# YTM32B1ME1 register map
Vendor: YTMicro; File version: 1.0
CPU: CM33 r0p4, little endian, MPU, FPU, 2 interrupt priority bits
Registers are 32-bit, read-write, reset 0x0 unless marked. A register's access mark holds for its fields unless they carry their own. Offsets are from the block's base; [hi:lo] are bit positions; {n}, {i} and the like mark numbered series.

## REGFILE — Register File
Base 0x40184000; register names take the prefix REGFILE_
{0x0+4i} DR{i} (i=0..7)
  [31:0] DATA — The data value stored at register file block. The register is only reseted by POR.

## GPIOA — General Purpose Input/Output
Base 0x40044000; register names take the prefix GPIOA_
0x00 PDOR
  [31:0] PDO — When configured for general-purpose output, it shows the logic level on the corresponding pin.
0x04 PSOR wo
  [31:0] PSO — Writing to this register will update the contents of the corresponding bit in PDOR.
    0=No change; 1=Corresponding bit in PDOR is set to logic 1
0x08 PCOR wo
  [31:0] PCO — Writing to this register will update the contents of the corresponding bit in PDOR.
    0=No change; 1=Corresponding bit in PDOR is set to logic 0
0x0C PTOR wo
  [31:0] PTO — Writing to this register will update the contents of the corresponding bit in PDOR.
    0=No change; 1=Corresponding bit in PDOR is set to the inverse of its existing logic state
0x10 PDIR ro
  [31:0] PDI — When configured for digital function, it shows the logic level on the corresponding pin. ewline When configured for analog function, it always reads 0.
0x14 POER
  [31:0] POE — Configure the corresponding pin for output.
    0=Port output disable; 1=Port output enable
0x18 PIER reset 0xFFFFFFFF
  [31:0] PIE — Configure the corresponding pin for input.
    0=Port input disable; 1=Port input enable
0x1C PIFR
  [31:0] PIF — Indicate the detection for the defined event in PCTRL[IRQC] of the corresponding pin.
    0=No event detected; 1=The event defined in PCTRL[IRQC] is detected
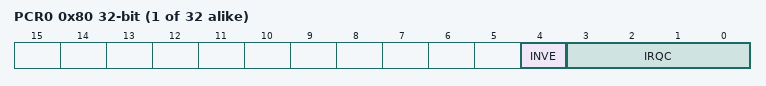
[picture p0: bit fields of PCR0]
{0x80+4i} PCR{i} (i=0..31)
  [4] INVE — Invert the input logic level when configured for digital function.
  [3:0] IRQC
    0=Disabled; 1=DMA request on rising edge; 2=DMA request on falling edge; 3=DMA request on either edge; 8=Interrupt when logic 0; 9=Interrupt on rising-edge; 10=Interrupt on falling-edge; 11=Interrupt on either edge; 12=Interrupt when logic 1

## GPIOB — General Purpose Input/Output
Base 0x40044100; register names take the prefix GPIOB_
Registers as GPIOA.

## GPIOC — General Purpose Input/Output
Base 0x40044200; register names take the prefix GPIOC_
Registers as GPIOA.

## GPIOD — General Purpose Input/Output
Base 0x40044300; register names take the prefix GPIOD_
Registers as GPIOA.

## GPIOE — General Purpose Input/Output
Base 0x40044400; register names take the prefix GPIOE_
Registers as GPIOA.

## PCTRLA — PORT Control
Base 0x40048000; register names take the prefix PCTRLA_
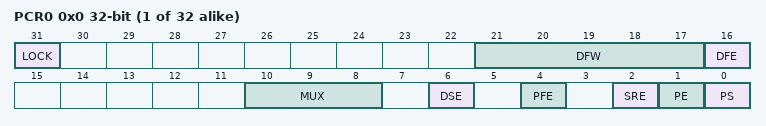
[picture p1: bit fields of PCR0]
{0x0+4i} PCR{i} (i=0..31) — Port control register
  [31] LOCK — Lock Enable configuration for digital pin muxing.
    0=Lock disable; 1=Lock enable, PCR's other bits and related GPIO's output register(PDOR,PSOR,PCOR,PTOR,POER) will be locked until write 0 to this bit
  [21:17] DFW — The digital filter configuration is valid in all digital pin muxing modes. Glitches that are longer than this register setting will pass through the digital filter, and glitches that are equal to or less than this register setting are filtered. Changing the filter length must be done only after all filters are disabled.
  [16] DFE
  [10:8] MUX — Not all pin muxing slots are implemented. Unimplemented pin muxing slots are reserved. Please refer to pinmux table for detailed peripheral functions. The corresponding pin is configured in the following pin muxing slot as follows:
    0=Alternative 0, Analog function, digital function is disabled; 1=Alternative 1, GPIO function; {v}=Alternative {v} (v=2..7)
  [6] DSE — Drive strength configuration for digital pin muxing.
    0=Low drive strength, if the pin is configured as a digital output; 1=High drive strength, if the pin is configured as a digital output
  [4] PFE — Passive filter configuration for digital pin muxing.
    0=Passive input filter is disabled; 1=Passive input filter is enabled, if the pin is configured as a digital input
  [2] SRE — Slew rate configuration for digital pin muxing.
    0=Fast slew rate, if the pin is configured as a digital output; 1=Slow slew rate, if the pin is configured as a digital output
  [1] PE — Pull configuration for digital pin muxing.
    0=Internal pullup or pulldown resistor is not enabled; 1=Internal pullup or pulldown resistor is enabled
  [0] PS — Pull configuration for digital pin muxing.
    0=Internal pulldown resistor is enabled, if PE field is set; 1=Internal pullup resistor is enabled, if PE field is set

## PCTRLB — PORT Control
Base 0x4004C000; register names take the prefix PCTRLB_
Registers as PCTRLA.

## PCTRLC — PORT Control
Base 0x40050000; register names take the prefix PCTRLC_
Registers as PCTRLA.

## PCTRLD — PORT Control
Base 0x40054000; register names take the prefix PCTRLD_
Registers as PCTRLA.

## PCTRLE — PORT Control
Base 0x40058000; register names take the prefix PCTRLE_
Registers as PCTRLA.
